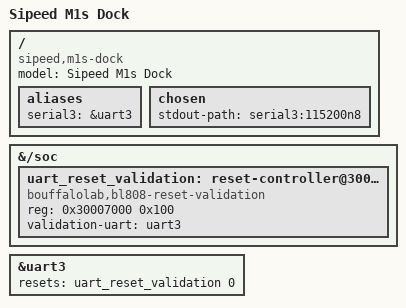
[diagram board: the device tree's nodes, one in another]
// SPDX-License-Identifier: (GPL-2.0+ OR MIT)

/dts-v1/;

#include "bl808-sipeed-m1s.dtsi"

/ {
	model = "Sipeed M1s Dock";
	compatible = "sipeed,m1s-dock", "sipeed,m1s", "bouffalolab,bl808";

	aliases {
		serial3 = &uart3;
	};

	chosen {
		stdout-path = "serial3:115200n8";
	};
};

&{/soc} {
	uart_reset_validation: reset-controller@30007000 {
		compatible = "bouffalolab,bl808-reset-validation";
		reg = <0x30007000 0x100>;
		#reset-cells = <1>;
		validation-uart = <&uart3>;
	};
};

&uart3 {
	resets = <&uart_reset_validation 0>;
	status = "okay";
};
